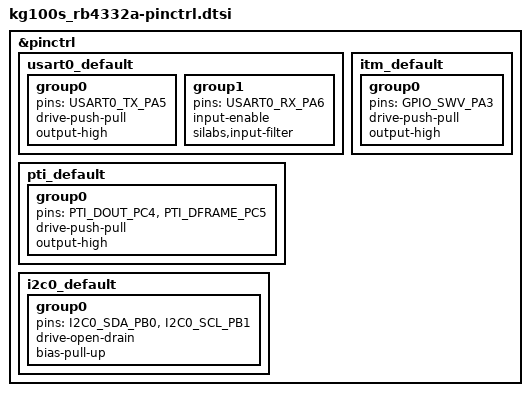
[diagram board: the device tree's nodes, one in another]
/*
 * Copyright (c) 2026 Martin Moya <martin.moya@focus.uy>
 *
 * SPDX-License-Identifier: Apache-2.0
 */

#include <zephyr/dt-bindings/pinctrl/silabs/xg21-pinctrl.h>

&pinctrl {
	/* vcom_tx: PA05, vcom_rx: PA06 */
	usart0_default: usart0_default {
		group0 {
			pins = <USART0_TX_PA5>;
			drive-push-pull;
			output-high;
		};

		group1 {
			pins = <USART0_RX_PA6>;
			input-enable;
			silabs,input-filter;
		};
	};

	/* pti_data: PC04, pti_sync: PC05 */
	pti_default: pti_default {
		group0 {
			pins = <PTI_DOUT_PC4>, <PTI_DFRAME_PC5>;
			drive-push-pull;
			output-high;
		};
	};

	/* dbg_swo: PA03 */
	itm_default: itm_default {
		group0 {
			pins = <GPIO_SWV_PA3>;
			drive-push-pull;
			output-high;
		};
	};

	/* i2c_sda: PB00, i2c_scl: PB01 */
	i2c0_default: i2c0_default {
		group0 {
			pins = <I2C0_SDA_PB0>, <I2C0_SCL_PB1>;
			drive-open-drain;
			bias-pull-up;
		};
	};
};
